# ATSAMA5D23 device description
Architecture: CORTEX-A5; Family: SAMA5; Series: SAMA5D2
Registers are 32-bit, read-write, no defined reset value unless marked. A register's access mark holds for its fields unless they carry their own. Offsets are from the block's base; [hi:lo] are bit positions; {n}, {i} and the like mark numbered series; 'fields as' and 'values as' point back to an identical list.

## PMC — Power Management Controller
Instances: PMC 0xF0014000
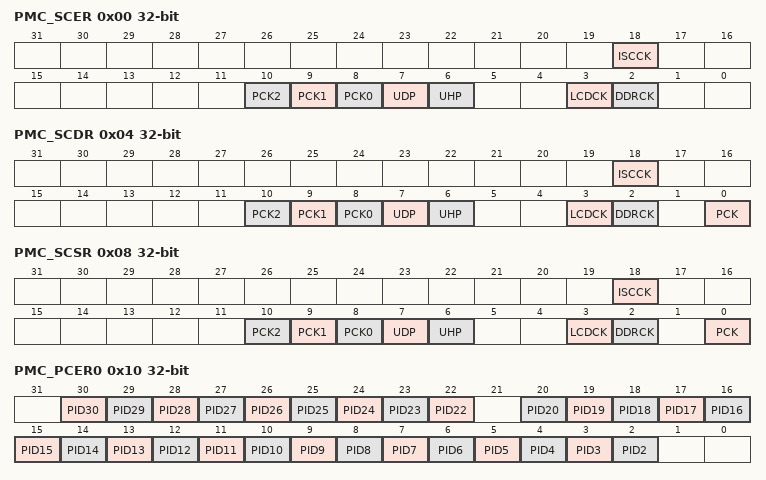
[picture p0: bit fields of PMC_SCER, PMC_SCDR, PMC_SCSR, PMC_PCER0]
0x00 PMC_SCER wo — System Clock Enable Register
  [18] ISCCK — ISC Clock Enable
  [10] PCK2 — Programmable Clock 2 Output Enable
  [9] PCK1 — Programmable Clock 1 Output Enable
  [8] PCK0 — Programmable Clock 0 Output Enable
  [7] UDP — USB Device Clock Enable
  [6] UHP — USB Host OHCI Clocks Enable
  [3] LCDCK — MCK2x Clock Enable
  [2] DDRCK — DDR Clock Enable
0x04 PMC_SCDR wo — System Clock Disable Register
  [18] ISCCK — ISC Clock Disable
  [10] PCK2 — Programmable Clock 2 Output Disable
  [9] PCK1 — Programmable Clock 1 Output Disable
  [8] PCK0 — Programmable Clock 0 Output Disable
  [7] UDP — USB Device Clock Enable
  [6] UHP — USB Host OHCI Clock Disable
  [3] LCDCK — MCK2x Clock Disable
  [2] DDRCK — DDR Clock Disable
  [0] PCK — Processor Clock Disable
0x08 PMC_SCSR ro — System Clock Status Register
  [18] ISCCK — ISC Clock Status
  [10] PCK2 — Programmable Clock 2 Output Status
  [9] PCK1 — Programmable Clock 1 Output Status
  [8] PCK0 — Programmable Clock 0 Output Status
  [7] UDP — USB Device Port Clock Status
  [6] UHP — USB Host Port Clock Status
  [3] LCDCK — MCK2x Clock Status
  [2] DDRCK — DDR Clock Status
  [0] PCK — Processor Clock Status
0x10 PMC_PCER0 wo — Peripheral Clock Enable Register 0
  [n] PID{n} (n=22..30) — Peripheral Clock {n} Enable
  [n] PID{n} (n=2..20) — Peripheral Clock {n} Enable
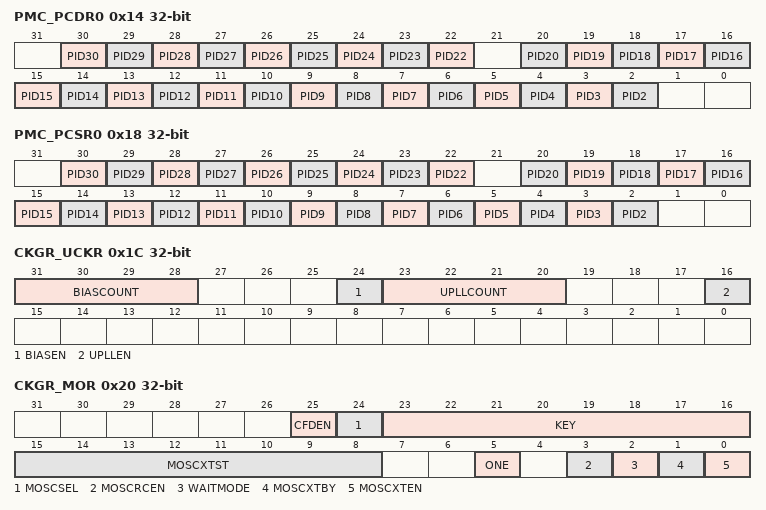
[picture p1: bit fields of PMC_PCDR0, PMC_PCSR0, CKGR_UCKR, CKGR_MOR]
0x14 PMC_PCDR0 wo — Peripheral Clock Disable Register 0
  [n] PID{n} (n=22..30) — Peripheral Clock {n} Disable
  [n] PID{n} (n=2..20) — Peripheral Clock {n} Disable
0x18 PMC_PCSR0 ro — Peripheral Clock Status Register 0
  [n] PID{n} (n=22..30) — Peripheral Clock {n} Status
  [n] PID{n} (n=2..20) — Peripheral Clock {n} Status
0x1C CKGR_UCKR — UTMI Clock Register
  [31:28] BIASCOUNT — UTMI BIAS Startup Time
  [24] BIASEN — UTMI BIAS Enable
  [23:20] UPLLCOUNT — UTMI PLL Startup Time
  [16] UPLLEN — UTMI PLL Enable
0x20 CKGR_MOR — Main Oscillator Register
  [25] CFDEN — Clock Failure Detector Enable
  [24] MOSCSEL — Main Clock Oscillator Selection
  [23:16] KEY — Password
    55=PASSWD (Writing any other value in this field aborts the write operation.)
  [15:8] MOSCXTST — 8 to 24 MHz Crystal Oscillator Startup Time
  [5] ONE — Must Be Set to 1
  [3] MOSCRCEN — 12 MHz RC Oscillator Enable
  [2] WAITMODE — Wait Mode Command (Write-only)
  [1] MOSCXTBY — 8 to 24 MHz Crystal Oscillator Bypass
  [0] MOSCXTEN — 8 to 24 MHz Crystal Oscillator Enable
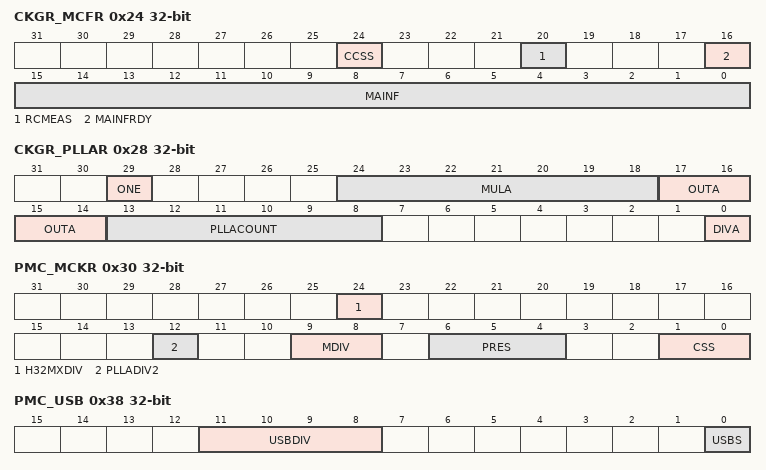
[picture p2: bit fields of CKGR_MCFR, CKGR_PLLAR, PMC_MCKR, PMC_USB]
0x24 CKGR_MCFR — Main Clock Frequency Register
  [24] CCSS — Counter Clock Source Selection
  [20] RCMEAS — RC Oscillator Frequency Measure (write-only)
  [16] MAINFRDY — Main Clock Frequency Measure Ready
  [15:0] MAINF — Main Clock Frequency
0x28 CKGR_PLLAR — PLLA Register
  [29] ONE — Must Be Set to 1
  [24:18] MULA — PLLA Multiplier
  [17:14] OUTA — PLLA Clock Frequency Range
  [13:8] PLLACOUNT — PLLA Counter
  [0] DIVA — Divider A
0x30 PMC_MCKR — Master Clock Register
  [24] H32MXDIV — AHB 32-bit Matrix Divisor
    0=The AHB 32-bit Matrix frequency is equal to the AHB 64-bit Matrix frequency. It is possible only if the AHB 64-bit Matrix frequency does not exceed 83 MHz.; 1=The AHB 32-bit Matrix frequency is equal to the AHB 64-bit Matrix frequency divided by 2
  [12] PLLADIV2 — PLLA Divisor by 2
  [9:8] MDIV — Master Clock Division
    0=EQ_PCK (Master Clock is Prescaler Output Clock divided by 1.Warning: DDRCK is not available.); 1=PCK_DIV2 (Master Clock is Prescaler Output Clock divided by 2. DDRCK is equal to MCK.); 2=PCK_DIV4 (Master Clock is Prescaler Output Clock divided by 4. DDRCK is equal to MCK.); 3=PCK_DIV3 (Master Clock is Prescaler Output Clock divided by 3. DDRCK is equal to MCK.)
  [6:4] PRES — Master/Processor Clock Prescaler
    0=CLOCK (Selected clock); 1=CLOCK_DIV2 (Selected clock divided by 2); 2=CLOCK_DIV4 (Selected clock divided by 4); 3=CLOCK_DIV8 (Selected clock divided by 8); 4=CLOCK_DIV16 (Selected clock divided by 16); 5=CLOCK_DIV32 (Selected clock divided by 32); 6=CLOCK_DIV64 (Selected clock divided by 64)
  [1:0] CSS — Master/Processor Clock Source Selection
    0=SLOW_CLK (Slow clock is selected); 1=MAIN_CLK (Main clock is selected); 2=PLLA_CLK (PLLACK is selected); 3=UPLL_CLK (UPLL Clock is selected)
0x38 PMC_USB — USB Clock Register
  [11:8] USBDIV — Divider for USB OHCI Clock
  [0] USBS — USB OHCI Input Clock Selection
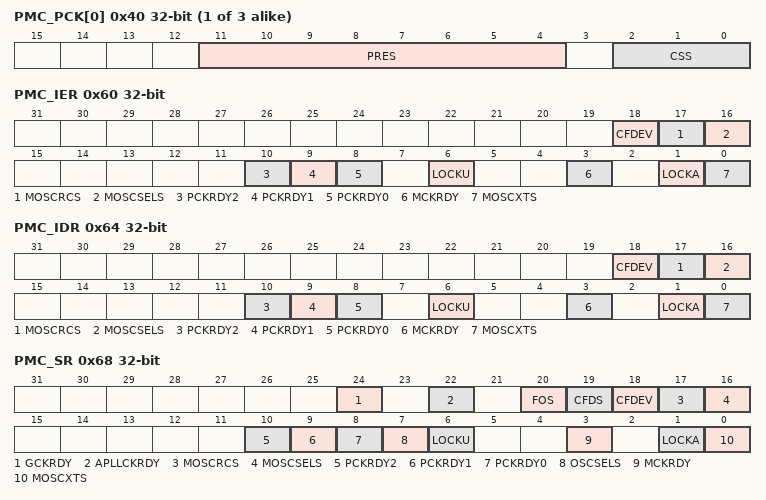
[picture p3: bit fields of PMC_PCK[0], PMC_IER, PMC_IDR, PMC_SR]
{0x40+4i} PMC_PCK[{i}] (i=0..2) — Programmable Clock 0 Register
  [11:4] PRES — Programmable Clock Prescaler
  [2:0] CSS — Master Clock Source Selection
    0=SLOW_CLK (Slow clock is selected); 1=MAIN_CLK (Main clock is selected); 2=PLLA_CLK (PLLACK is selected); 3=UPLL_CLK (UPLL Clock is selected); 4=MCK_CLK (Master Clock is selected); 5=AUDIO_CLK (Audio PLL clock is selected)
0x60 PMC_IER wo — Interrupt Enable Register
  [18] CFDEV — Clock Failure Detector Event Interrupt Enable
  [17] MOSCRCS — 12 MHz RC Oscillator Status Interrupt Enable
  [16] MOSCSELS — Main Clock Source Oscillator Selection Status Interrupt Enable
  [10] PCKRDY2 — Programmable Clock Ready 2 Interrupt Enable
  [9] PCKRDY1 — Programmable Clock Ready 1 Interrupt Enable
  [8] PCKRDY0 — Programmable Clock Ready 0 Interrupt Enable
  [6] LOCKU — UTMI PLL Lock Interrupt Enable
  [3] MCKRDY — Master Clock Ready Interrupt Enable
  [1] LOCKA — PLLA Lock Interrupt Enable
  [0] MOSCXTS — 8 to 24 MHz Crystal Oscillator Status Interrupt Enable
0x64 PMC_IDR wo — Interrupt Disable Register
  [18] CFDEV — Clock Failure Detector Event Interrupt Disable
  [17] MOSCRCS — 12 MHz RC Oscillator Status Interrupt Disable
  [16] MOSCSELS — Main Oscillator Clock Source Selection Status Interrupt Disable
  [10] PCKRDY2 — Programmable Clock Ready 2 Interrupt Disable
  [9] PCKRDY1 — Programmable Clock Ready 1 Interrupt Disable
  [8] PCKRDY0 — Programmable Clock Ready 0 Interrupt Disable
  [6] LOCKU — UTMI PLL Lock Interrupt Enable
  [3] MCKRDY — Master Clock Ready Interrupt Disable
  [1] LOCKA — PLLA Lock Interrupt Disable
  [0] MOSCXTS — 8 to 24 MHz Crystal Oscillator Status Interrupt Disable
0x68 PMC_SR ro — Status Register
  [24] GCKRDY — Generic Clock Status
  [22] APLLCKRDY — Audio PLL Lock Status
  [20] FOS — Clock Failure Detector Fault Output Status
  [19] CFDS — Clock Failure Detector Status
  [18] CFDEV — Clock Failure Detector Event
  [17] MOSCRCS — 12 MHz RC Oscillator Status
  [16] MOSCSELS — Main Oscillator Selection Status
  [10] PCKRDY2 — Programmable Clock Ready Status
  [9] PCKRDY1 — Programmable Clock Ready Status
  [8] PCKRDY0 — Programmable Clock Ready Status
  [7] OSCSELS — Slow Clock Oscillator Selection
  [6] LOCKU — UPLL Clock Status
  [3] MCKRDY — Master Clock Status
  [1] LOCKA — PLLA Lock Status
  [0] MOSCXTS — 8 to 24 MHz Crystal Oscillator Status
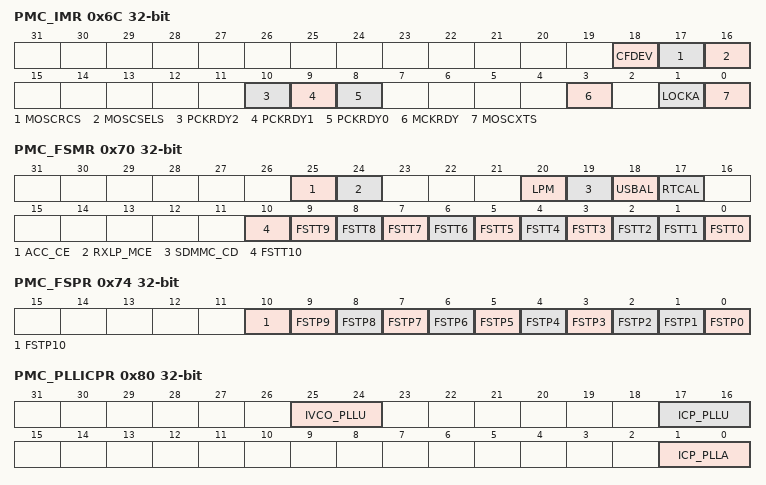
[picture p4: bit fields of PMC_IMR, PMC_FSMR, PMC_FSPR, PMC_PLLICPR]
0x6C PMC_IMR ro — Interrupt Mask Register
  [18] CFDEV — Clock Failure Detector Event Interrupt Mask
  [17] MOSCRCS — 12 MHz RC Oscillator Status Interrupt Mask
  [16] MOSCSELS — Main Oscillator Clock Source Selection Status Interrupt Mask
  [10] PCKRDY2 — Programmable Clock Ready 2 Interrupt Mask
  [9] PCKRDY1 — Programmable Clock Ready 1 Interrupt Mask
  [8] PCKRDY0 — Programmable Clock Ready 0 Interrupt Mask
  [3] MCKRDY — Master Clock Ready Interrupt Mask
  [1] LOCKA — PLLA Lock Interrupt Mask
  [0] MOSCXTS — 8 to 24 MHz Crystal Oscillator Status Interrupt Mask
0x70 PMC_FSMR — Fast Startup Mode Register
  [25] ACC_CE — Fast Startup from Analog Comparator Controller Comparison Enable
  [24] RXLP_MCE — Fast Startup from Backup UART Receive Match Condition Enable
  [20] LPM — Low-power Mode
  [19] SDMMC_CD — Fast Startup from SDMMC Card Detect Enable
  [18] USBAL — Fast Startup from USB Resume Enable
  [17] RTCAL — Fast Startup from RTC Alarm Enable
  [10] FSTT10 — Fast Start-up from GMAC Wake-up On LAN Enable
  [n] FSTT{n} (n=2..9) — Fast Startup from PIOBU0-7 Input Enable
  [1] FSTT1 — Fast Startup from Security Module Enable
  [0] FSTT0 — Fast Startup from WKUP Pin Enable
0x74 PMC_FSPR — Fast Startup Polarity Register
  [10] FSTP10 — GMAC Wake-up On LAN Polarity for Fast Start-up
  [n] FSTP{n} (n=2..9) — PIOBU0-7 Pin Polarity for Fast Startup
  [1] FSTP1 — Security Module Polarity for Fast Startup
  [0] FSTP0 — WKUP Pin Polarity for Fast Startup
0x78 PMC_FOCR wo — Fault Output Clear Register
  [0] FOCLR — Fault Output Clear
0x80 PMC_PLLICPR — PLL Charge Pump Current Register
  [25:24] IVCO_PLLU — Voltage Control Output Current PLL UTMI
  [17:16] ICP_PLLU — Charge Pump Current PLL UTMI
  [1:0] ICP_PLLA — Charge Pump Current
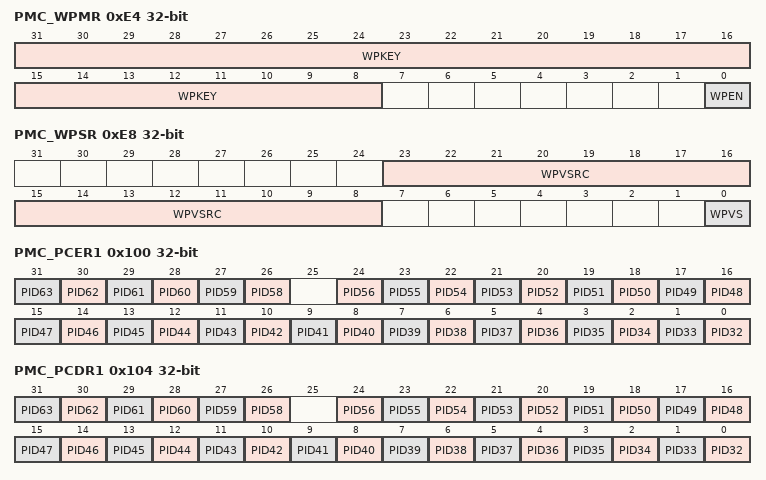
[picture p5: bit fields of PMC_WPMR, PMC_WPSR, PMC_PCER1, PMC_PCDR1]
0xE4 PMC_WPMR — Write ProtectIon Mode Register
  [31:8] WPKEY — Write Protection Key
    0x504D43=PASSWD (Writing any other value in this field aborts the write operation of the WPEN bit.Always reads as 0.)
  [0] WPEN — Write Protection Enable
0xE8 PMC_WPSR ro — Write Protection Status Register
  [23:8] WPVSRC — Write Protection Violation Source
  [0] WPVS — Write Protection Violation Status
0x100 PMC_PCER1 wo — Peripheral Clock Enable Register 1
  [n-32] PID{n} (n=58..63) — Peripheral Clock {n} Enable
  [n-32] PID{n} (n=32..56) — Peripheral Clock {n} Enable
0x104 PMC_PCDR1 wo — Peripheral Clock Disable Register 1
  [n-32] PID{n} (n=58..63) — Peripheral Clock {n} Disable
  [n-32] PID{n} (n=32..56) — Peripheral Clock {n} Disable
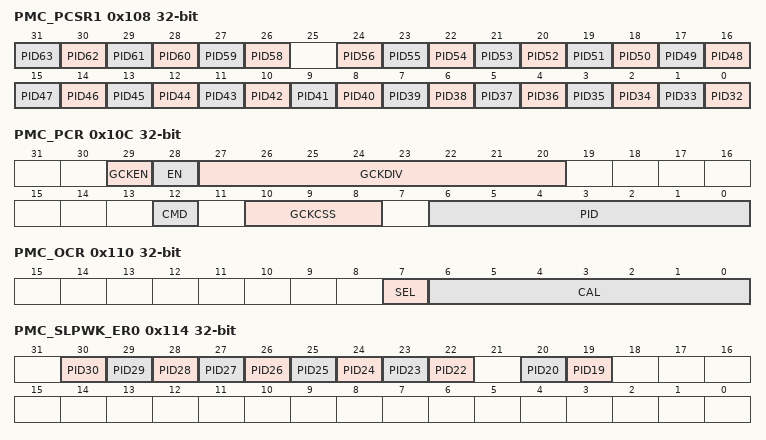
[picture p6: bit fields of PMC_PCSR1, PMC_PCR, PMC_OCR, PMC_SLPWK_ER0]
0x108 PMC_PCSR1 ro — Peripheral Clock Status Register 1
  [n-32] PID{n} (n=58..63) — Peripheral Clock {n} Status
  [n-32] PID{n} (n=32..56) — Peripheral Clock {n} Status
0x10C PMC_PCR — Peripheral Control Register
  [29] GCKEN — Generic Clock Enable
  [28] EN — Enable
  [27:20] GCKDIV — Generic Clock Division Ratio
  [12] CMD — Command
  [10:8] GCKCSS — Generic Clock Source Selection
    values as PMC_PCK[0].CSS
  [6:0] PID — Peripheral ID
0x110 PMC_OCR — Oscillator Calibration Register
  [7] SEL — Selection of RC Oscillator Calibration Bits
  [6:0] CAL — 12 MHz RC Oscillator Calibration Bits
0x114 PMC_SLPWK_ER0 wo — SleepWalking Enable Register 0
  [n] PID{n} (n=22..30) — Peripheral {n} SleepWalking Enable
  [20] PID20 — Peripheral 20 SleepWalking Enable
  [19] PID19 — Peripheral 19 SleepWalking Enable
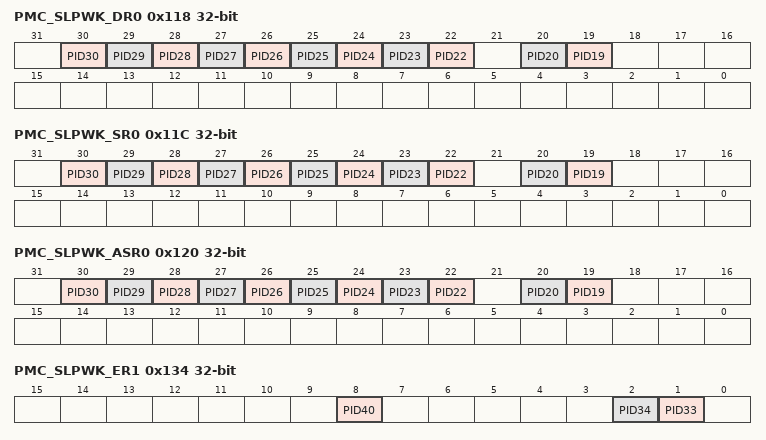
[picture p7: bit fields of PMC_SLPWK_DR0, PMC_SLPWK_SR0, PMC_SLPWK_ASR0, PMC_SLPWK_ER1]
0x118 PMC_SLPWK_DR0 wo — SleepWalking Disable Register 0
  [n] PID{n} (n=22..30) — Peripheral {n} SleepWalking Disable
  [20] PID20 — Peripheral 20 SleepWalking Disable
  [19] PID19 — Peripheral 19 SleepWalking Disable
0x11C PMC_SLPWK_SR0 ro — SleepWalking Status Register 0
  [n] PID{n} (n=22..30) — Peripheral {n} SleepWalking Status
  [20] PID20 — Peripheral 20 SleepWalking Status
  [19] PID19 — Peripheral 19 SleepWalking Status
0x120 PMC_SLPWK_ASR0 ro — SleepWalking Activity Status Register 0
  [n] PID{n} (n=22..30) — Peripheral {n} Activity Status
  [20] PID20 — Peripheral 20 Activity Status
  [19] PID19 — Peripheral 19 Activity Status
0x134 PMC_SLPWK_ER1 wo — SleepWalking Enable Register 1
  [8] PID40 — Peripheral 40 SleepWalking Enable
  [2] PID34 — Peripheral 34 SleepWalking Enable
  [1] PID33 — Peripheral 33 SleepWalking Enable
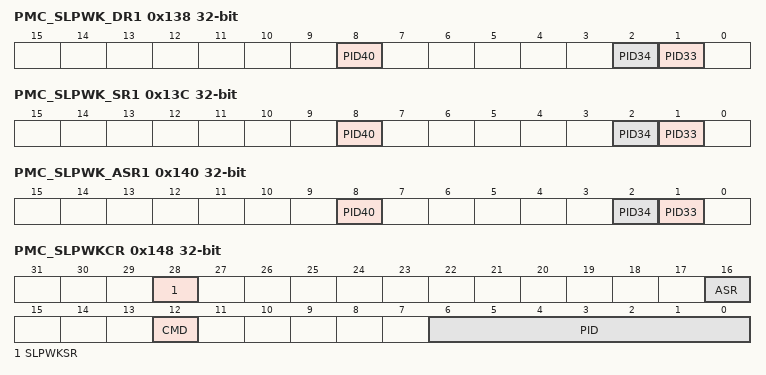
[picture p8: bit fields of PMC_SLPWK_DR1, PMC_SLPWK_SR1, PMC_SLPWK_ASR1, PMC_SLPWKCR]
0x138 PMC_SLPWK_DR1 wo — SleepWalking Disable Register 1
  [8] PID40 — Peripheral 40 SleepWalking Disable
  [2] PID34 — Peripheral 34 SleepWalking Disable
  [1] PID33 — Peripheral 33 SleepWalking Disable
0x13C PMC_SLPWK_SR1 ro — SleepWalking Status Register 1
  [8] PID40 — Peripheral 40 SleepWalking Status
  [2] PID34 — Peripheral 34 SleepWalking Status
  [1] PID33 — Peripheral 33 SleepWalking Status
0x140 PMC_SLPWK_ASR1 ro — SleepWalking Activity Status Register 1
  [8] PID40 — Peripheral 40 Activity Status
  [2] PID34 — Peripheral 34 Activity Status
  [1] PID33 — Peripheral 33 Activity Status
0x144 PMC_SLPWK_AIPR ro — SleepWalking Activity In Progress Register
  [0] AIP — Activity In Progress
0x148 PMC_SLPWKCR — SleepWalking Control Register
  [28] SLPWKSR — SleepWalking Status Register
  [16] ASR — Activity Status Register
  [12] CMD — Command
  [6:0] PID — Peripheral ID
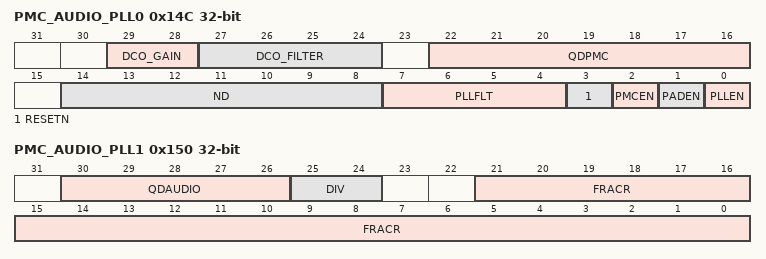
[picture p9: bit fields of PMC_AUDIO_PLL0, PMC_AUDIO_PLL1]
0x14C PMC_AUDIO_PLL0 — Audio PLL Register 0
  [29:28] DCO_GAIN — Digitally Controlled Oscillator Gain Selection
  [27:24] DCO_FILTER — Digitally Controlled Oscillator Filter Selection
  [22:16] QDPMC — Output Divider Ratio for PMC Clock
  [14:8] ND — Loop Divider Ratio
  [7:4] PLLFLT — PLL Loop Filter Selection
  [3] RESETN — Audio PLL Reset
  [2] PMCEN — PMC Clock Enable
  [1] PADEN — Pad Clock Enable
  [0] PLLEN — PLL Enable
0x150 PMC_AUDIO_PLL1 — Audio PLL Register 1
  [30:26] QDAUDIO — Output Divider Ratio for Pad Clock
  [25:24] DIV — Divider Value
    2=Divide by 2; 3=Divide by 3
  [21:0] FRACR — Fractional Loop Divider Setting
